# ATSAMA5D27WLSOM1 device description
Architecture: CORTEX-A5; Family: SAMA5; Series: SAMA5D2
Registers are 32-bit, read-write, no defined reset value unless marked. A register's access mark holds for its fields unless they carry their own. Offsets are from the block's base; [hi:lo] are bit positions; lines under a group give offsets from that group; {n}, {i} and the like mark numbered series; 'fields as' and 'values as' point back to an identical list; <NAME> marks a mode.

## TC — Timer Counter
Instances: TC0 0xF800C000, TC1 0xF8010000
{0x0+0x40*i} TC_CHANNEL[{i}] (i=0..2) group
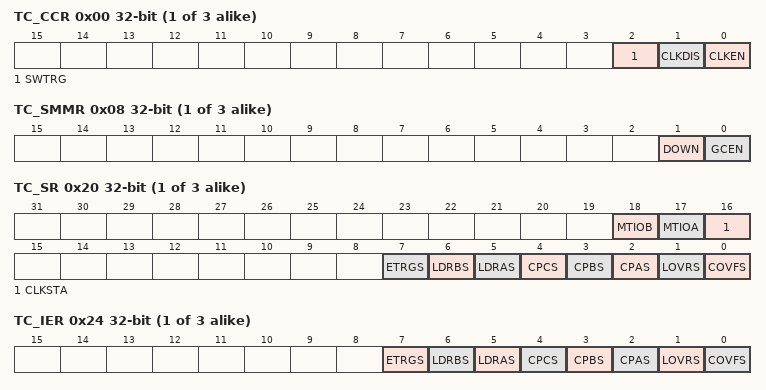
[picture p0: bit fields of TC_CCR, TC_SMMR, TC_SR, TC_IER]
  0x00 TC_CCR wo — Channel Control Register
    [2] SWTRG — Software Trigger Command
    [1] CLKDIS — Counter Clock Disable Command
    [0] CLKEN — Counter Clock Enable Command
  0x04 TC_CMR (modes: CAPTURE when TC_CMR.WAVE=0x0; WAVEFORM when TC_CMR.WAVE=0x1) — Channel Mode Register
    [15] WAVE — Waveform Mode
    [5:4] BURST — Burst Signal Selection
      0=NONE (The clock is not gated by an external signal.); 1=XC0 (XC0 is ANDed with the selected clock.); 2=XC1 (XC1 is ANDed with the selected clock.); 3=XC2 (XC2 is ANDed with the selected clock.)
    [3] CLKI — Clock Invert
    [2:0] TCCLKS — Clock Selection
      0=TIMER_CLOCK1 (Clock selected: internal GCLK [35], GCLK [36] clock signal (from PMC)); 1=TIMER_CLOCK2 (Clock selected: internal System bus clock divided by 8 clock signal (from PMC)); 2=TIMER_CLOCK3 (Clock selected: internal System bus clock divided by 32 clock signal (from PMC)); 3=TIMER_CLOCK4 (Clock selected: internal System bus clock divided by 128 clock signal (from PMC)); 4=TIMER_CLOCK5 (Clock selected: internal slow_clock clock signal (from PMC)); 5=XC0 (Clock selected: XC0); 6=XC1 (Clock selected: XC1); 7=XC2 (Clock selected: XC2)
    [22:20] SBSMPLR <CAPTURE> — Loading Edge Subsampling Ratio
      0=ONE (Load a Capture register each selected edge); 1=HALF (Load a Capture register every 2 selected edges); 2=FOURTH (Load a Capture register every 4 selected edges); 3=EIGHTH (Load a Capture register every 8 selected edges); 4=SIXTEENTH (Load a Capture register every 16 selected edges)
    [19:18] LDRB <CAPTURE> — RB Loading Edge Selection
      0=NONE; 1=RISING (Rising edge of TIOAx); 2=FALLING (Falling edge of TIOAx); 3=EDGE (Each edge of TIOAx)
    [17:16] LDRA <CAPTURE> — RA Loading Edge Selection
      values as LDRB<CAPTURE>
    [14] CPCTRG <CAPTURE> — RC Compare Trigger Enable
    [10] ABETRG <CAPTURE> — TIOAx or TIOBx External Trigger Selection
    [9:8] ETRGEDG <CAPTURE> — External Trigger Edge Selection
      0=NONE (The clock is not gated by an external signal.); 1=RISING (Rising edge); 2=FALLING (Falling edge); 3=EDGE (Each edge)
    [7] LDBDIS <CAPTURE> — Counter Clock Disable with RB Loading
    [6] LDBSTOP <CAPTURE> — Counter Clock Stopped with RB Loading
    [31:30] BSWTRG <WAVEFORM> — Software Trigger Effect on TIOBx
      0=NONE; 1=SET; 2=CLEAR; 3=TOGGLE
    [29:28] BEEVT <WAVEFORM> — External Event Effect on TIOBx
      0=NONE; 1=SET; 2=CLEAR; 3=TOGGLE
    [27:26] BCPC <WAVEFORM> — RC Compare Effect on TIOBx
      0=NONE; 1=SET; 2=CLEAR; 3=TOGGLE
    [25:24] BCPB <WAVEFORM> — RB Compare Effect on TIOBx
      0=NONE; 1=SET; 2=CLEAR; 3=TOGGLE
    [23:22] ASWTRG <WAVEFORM> — Software Trigger Effect on TIOAx
      0=NONE; 1=SET; 2=CLEAR; 3=TOGGLE
    [21:20] AEEVT <WAVEFORM> — External Event Effect on TIOAx
      0=NONE; 1=SET; 2=CLEAR; 3=TOGGLE
    [19:18] ACPC <WAVEFORM> — RC Compare Effect on TIOAx
      0=NONE; 1=SET; 2=CLEAR; 3=TOGGLE
    [17:16] ACPA <WAVEFORM> — RA Compare Effect on TIOAx
      0=NONE; 1=SET; 2=CLEAR; 3=TOGGLE
    [14:13] WAVSEL <WAVEFORM> — Waveform Selection
      0=UP (UP mode without automatic trigger on RC Compare); 1=UPDOWN (UPDOWN mode without automatic trigger on RC Compare); 2=UP_RC (UP mode with automatic trigger on RC Compare); 3=UPDOWN_RC (UPDOWN mode with automatic trigger on RC Compare)
    [12] ENETRG <WAVEFORM> — External Event Trigger Enable
    [11:10] EEVT <WAVEFORM> — External Event Selection
      0=TIOB; 1=XC0; 2=XC1; 3=XC2
    [9:8] EEVTEDG <WAVEFORM> — External Event Edge Selection
      0=NONE; 1=RISING (Rising edge); 2=FALLING (Falling edge); 3=EDGE (Each edge)
    [7] CPCDIS <WAVEFORM> — Counter Clock Disable with RC Loading
    [6] CPCSTOP <WAVEFORM> — Counter Clock Stopped with RC Compare
  0x08 TC_SMMR — Stepper Motor Mode Register
    [1] DOWN — Down Count
    [0] GCEN — Gray Count Enable
  0x0C TC_RAB ro — Register AB
    [31:0] RAB — Register A or Register B
  0x10 TC_CV ro — Counter Value
  0x14 TC_RA — Register A
  0x18 TC_RB — Register B
  0x1C TC_RC — Register C
  0x20 TC_SR ro — Interrupt Status Register
    [18] MTIOB — TIOBx Mirror
    [17] MTIOA — TIOAx Mirror
    [16] CLKSTA — Clock Enabling Status
    [7] ETRGS — External Trigger Status (cleared on read)
    [6] LDRBS — RB Loading Status (cleared on read)
    [5] LDRAS — RA Loading Status (cleared on read)
    [4] CPCS — RC Compare Status (cleared on read)
    [3] CPBS — RB Compare Status (cleared on read)
    [2] CPAS — RA Compare Status (cleared on read)
    [1] LOVRS — Load Overrun Status (cleared on read)
    [0] COVFS — Counter Overflow Status (cleared on read)
  0x24 TC_IER wo (atomic set of TC_IMR) — Interrupt Enable Register
    [7] ETRGS — External Trigger
    [6] LDRBS — RB Loading
    [5] LDRAS — RA Loading
    [4] CPCS — RC Compare
    [3] CPBS — RB Compare
    [2] CPAS — RA Compare
    [1] LOVRS — Load Overrun
    [0] COVFS — Counter Overflow
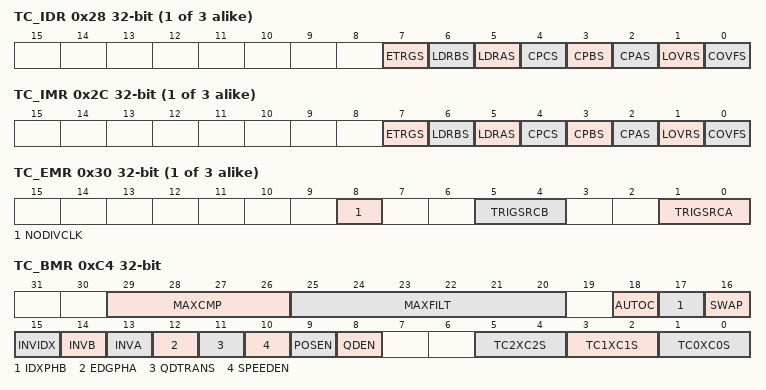
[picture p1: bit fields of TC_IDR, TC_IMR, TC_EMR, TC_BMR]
  0x28 TC_IDR wo (atomic clear of TC_IMR) — Interrupt Disable Register
    fields as TC_CHANNEL[0].TC_IER
  0x2C TC_IMR ro (atomic read) — Interrupt Mask Register
    [7] ETRGS
    [6] LDRBS — RB Loading
    [5] LDRAS — RA Loading
    [4] CPCS — RC Compare
    [3] CPBS — RB Compare
    [2] CPAS — RA Compare
    [1] LOVRS — Load Overrun
    [0] COVFS — Counter Overflow
  0x30 TC_EMR — Extended Mode Register
    [8] NODIVCLK — No Divided Clock
    [5:4] TRIGSRCB — Trigger Source for Input B
      0=EXTERNAL_TIOBx (The trigger/capture input B is driven by external pin TIOBx); 1=PWMx (For TC0 to TC10: The trigger/capture input B is driven internally by the comparator output (see Figure 7-16) of the PWMx.For TC11: The trigger/capture input B is driven internally by the GTSUCOMP signal of the Ethernet MAC (GMAC).)
    [1:0] TRIGSRCA — Trigger Source for Input A
      0=EXTERNAL_TIOAx (The trigger/capture input A is driven by external pin TIOAx); 1=PWMx (The trigger/capture input A is driven internally by PWMx)
0xC0 TC_BCR wo — Block Control Register
  [0] SYNC — Synchro Command
0xC4 TC_BMR — Block Mode Register
  [29:26] MAXCMP — Maximum Consecutive Missing Pulses
  [25:20] MAXFILT — Maximum Filter
  [18] AUTOC — AutoCorrection of missing pulses
    0=DISABLED (The detection and autocorrection function is disabled.); 1=ENABLED (The detection and autocorrection function is enabled.)
  [17] IDXPHB — Index Pin is PHB Pin
  [16] SWAP — Swap PHA and PHB
  [15] INVIDX — Inverted Index
  [14] INVB — Inverted PHB
  [13] INVA — Inverted PHA
  [12] EDGPHA — Edge on PHA Count Mode
  [11] QDTRANS — Quadrature Decoding Transparent
  [10] SPEEDEN — Speed Enabled
  [9] POSEN — Position Enabled
  [8] QDEN — Quadrature Decoder Enabled
  [5:4] TC2XC2S — External Clock Signal 2 Selection
    0=TCLK2 (Signal connected to XC2: TCLK2); 2=TIOA0 (Signal connected to XC2: TIOA0); 3=TIOA1 (Signal connected to XC2: TIOA1)
  [3:2] TC1XC1S — External Clock Signal 1 Selection
    0=TCLK1 (Signal connected to XC1: TCLK1); 2=TIOA0 (Signal connected to XC1: TIOA0); 3=TIOA2 (Signal connected to XC1: TIOA2)
  [1:0] TC0XC0S — External Clock Signal 0 Selection
    0=TCLK0 (Signal connected to XC0: TCLK0); 2=TIOA1 (Signal connected to XC0: TIOA1); 3=TIOA2 (Signal connected to XC0: TIOA2)
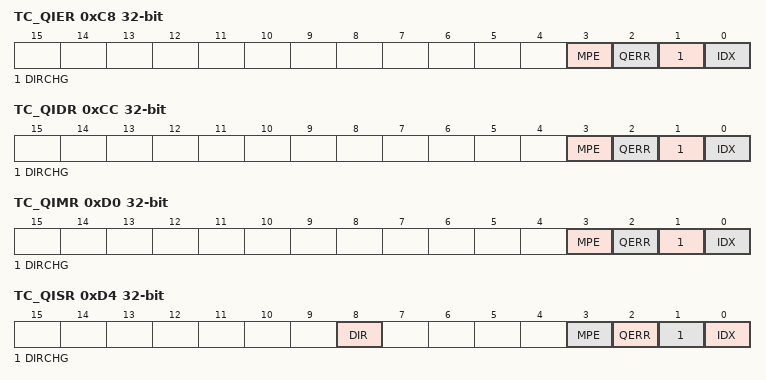
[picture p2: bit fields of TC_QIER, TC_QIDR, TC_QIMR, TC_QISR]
0xC8 TC_QIER wo (atomic set of TC_QIMR) — QDEC Interrupt Enable Register
  [3] MPE — Consecutive Missing Pulse Error
  [2] QERR — Quadrature Error
  [1] DIRCHG — Direction Change
  [0] IDX — Index
0xCC TC_QIDR wo (atomic clear of TC_QIMR) — QDEC Interrupt Disable Register
  fields as TC_QIER
0xD0 TC_QIMR ro (atomic read) — QDEC Interrupt Mask Register
  fields as TC_QIER
0xD4 TC_QISR ro (atomic clear) — QDEC Interrupt Status Register
  [8] DIR — Direction
  [3] MPE — Consecutive Missing Pulse Error
  [2] QERR — Quadrature Error
  [1] DIRCHG — Direction Change
  [0] IDX — Index
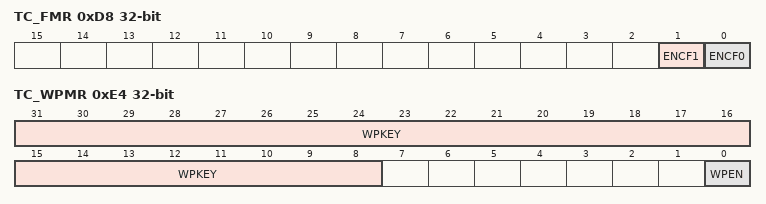
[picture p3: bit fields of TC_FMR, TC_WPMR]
0xD8 TC_FMR — Fault Mode Register
  [1] ENCF1 — Enable Compare Fault Channel 1
  [0] ENCF0 — Enable Compare Fault Channel 0
0xE4 TC_WPMR — Write Protection Mode Register
  [31:8] WPKEY — Write Protection Key
    0x54494D=PASSWD (Writing any other value in this field aborts the write operation of the WPEN bit.Always reads as 0.)
  [0] WPEN — Write Protection Enable
